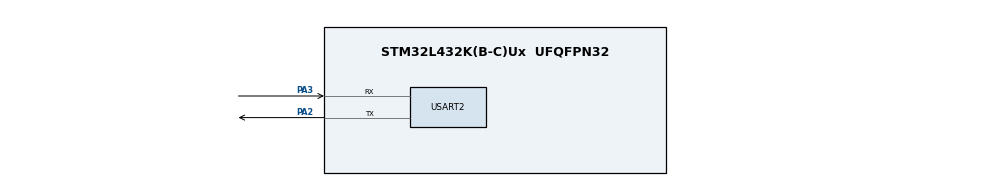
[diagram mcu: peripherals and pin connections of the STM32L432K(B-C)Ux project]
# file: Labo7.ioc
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Dma.Request0=USART2_RX
Dma.Request1=USART2_TX
Dma.USART2_RX.0.Direction=DMA_PERIPH_TO_MEMORY
Dma.USART2_RX.0.Instance=DMA1_Channel6
Dma.USART2_RX.0.MemDataAlignment=DMA_MDATAALIGN_BYTE
Dma.USART2_RX.0.MemInc=DMA_MINC_ENABLE
Dma.USART2_RX.0.Mode=DMA_NORMAL
Dma.USART2_RX.0.PeriphDataAlignment=DMA_PDATAALIGN_BYTE
Dma.USART2_RX.0.PeriphInc=DMA_PINC_DISABLE
Dma.USART2_RX.0.Priority=DMA_PRIORITY_LOW
Dma.USART2_TX.1.Direction=DMA_MEMORY_TO_PERIPH
Dma.USART2_TX.1.Instance=DMA1_Channel7
Dma.USART2_TX.1.MemDataAlignment=DMA_MDATAALIGN_BYTE
Dma.USART2_TX.1.MemInc=DMA_MINC_ENABLE
Dma.USART2_TX.1.Mode=DMA_NORMAL
Dma.USART2_TX.1.PeriphDataAlignment=DMA_PDATAALIGN_BYTE
Dma.USART2_TX.1.PeriphInc=DMA_PINC_DISABLE
Dma.USART2_TX.1.Priority=DMA_PRIORITY_LOW
Mcu.Family=STM32L4
Mcu.Name=STM32L432K(B-C)Ux
Mcu.Package=UFQFPN32
NVIC.DMA1_Channel6_IRQn=true\:0\:0\:false\:false\:true\:false\:true\:true
NVIC.DMA1_Channel7_IRQn=true\:0\:0\:false\:false\:true\:false\:true\:true
NVIC.PriorityGroup=NVIC_PRIORITYGROUP_4
PA2.Mode=Asynchronous
PA2.Signal=USART2_TX
PA3.Mode=Asynchronous
PA3.Signal=USART2_RX
ProjectManager.HeapSize=0x200
ProjectManager.StackSize=0x400
ProjectManager.TargetToolchain=STM32CubeIDE
RCC.HSE_VALUE=8000000
RCC.HSI48_VALUE=48000000
RCC.HSI_VALUE=16000000
RCC.LSE_VALUE=32768
RCC.MSI_VALUE=4000000
RCC.VCOOutputFreq_Value=32000000
USART2.VirtualMode-Asynchronous=VM_ASYNC
board=custom

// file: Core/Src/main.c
/* USER CODE BEGIN Header */
/**
  ******************************************************************************
  * @file           : main.c
  * @brief          : Main program body
  ******************************************************************************
  * @attention
  *
  * Copyright (c) 2022 STMicroelectronics.
  * All rights reserved.
  *
  * This software is licensed under terms that can be found in the LICENSE file
  * in the root directory of this software component.
  * If no LICENSE file comes with this software, it is provided AS-IS.
  *
  ******************************************************************************
  */
/* USER CODE END Header */
#include "main.h"

/* USER CODE BEGIN Includes */
#include "string.h"
/* USER CODE END Includes */

UART_HandleTypeDef huart2;
DMA_HandleTypeDef hdma_usart2_rx;
DMA_HandleTypeDef hdma_usart2_tx;

void SystemClock_Config(void);
static void MX_GPIO_Init(void);
static void MX_DMA_Init(void);
static void MX_USART2_UART_Init(void);

/* USER CODE BEGIN 0 */
//uint8_t dataArrived = 0;
uint8_t data[4] = "";
/* USER CODE END 0 */

int main(void)
{

  /* MCU Configuration--------------------------------------------------------*/

  /* Reset of all peripherals, Initializes the Flash interface and the Systick. */
  HAL_Init();

  /* Configure the system clock */
  SystemClock_Config();

  /* Initialize all configured peripherals */
  MX_GPIO_Init();
  MX_DMA_Init();
  MX_USART2_UART_Init();

  /* Infinite loop */
  /* USER CODE BEGIN WHILE */
  HAL_UART_Receive_DMA(&huart2, data, 4);
 // while(!dataArrived);
  while (1)
  {
    /* USER CODE END WHILE */
	  HAL_UART_Transmit_DMA(&huart2, (uint8_t*)"Hijo solo te veia y ve como amigo, ya basta por favor!!!\n\r", strlen("Gaby, Vid lleguen temprano por fa!!!\n\r"));
	  HAL_Delay(1000);
  }
}

void SystemClock_Config(void)
{
  RCC_OscInitTypeDef RCC_OscInitStruct = {0};
  RCC_ClkInitTypeDef RCC_ClkInitStruct = {0};

  /** Configure the main internal regulator output voltage
  */
  if (HAL_PWREx_ControlVoltageScaling(PWR_REGULATOR_VOLTAGE_SCALE1) != HAL_OK)
  {
    Error_Handler();
  }

  /** Initializes the RCC Oscillators according to the specified parameters
  * in the RCC_OscInitTypeDef structure.
  */
  RCC_OscInitStruct.OscillatorType = RCC_OSCILLATORTYPE_MSI;
  RCC_OscInitStruct.MSIState = RCC_MSI_ON;
  RCC_OscInitStruct.MSICalibrationValue = 0;
  RCC_OscInitStruct.MSIClockRange = RCC_MSIRANGE_6;
  RCC_OscInitStruct.PLL.PLLState = RCC_PLL_NONE;
  if (HAL_RCC_OscConfig(&RCC_OscInitStruct) != HAL_OK)
  {
    Error_Handler();
  }

  /** Initializes the CPU, AHB and APB buses clocks
  */
  RCC_ClkInitStruct.ClockType = RCC_CLOCKTYPE_HCLK|RCC_CLOCKTYPE_SYSCLK
                              |RCC_CLOCKTYPE_PCLK1|RCC_CLOCKTYPE_PCLK2;
  RCC_ClkInitStruct.SYSCLKSource = RCC_SYSCLKSOURCE_MSI;
  RCC_ClkInitStruct.AHBCLKDivider = RCC_SYSCLK_DIV1;
  RCC_ClkInitStruct.APB1CLKDivider = RCC_HCLK_DIV1;
  RCC_ClkInitStruct.APB2CLKDivider = RCC_HCLK_DIV1;

  if (HAL_RCC_ClockConfig(&RCC_ClkInitStruct, FLASH_LATENCY_0) != HAL_OK)
  {
    Error_Handler();
  }
}

static void MX_USART2_UART_Init(void)
{

  huart2.Instance = USART2;
  huart2.Init.BaudRate = 115200;
  huart2.Init.WordLength = UART_WORDLENGTH_8B;
  huart2.Init.StopBits = UART_STOPBITS_1;
  huart2.Init.Parity = UART_PARITY_NONE;
  huart2.Init.Mode = UART_MODE_TX_RX;
  huart2.Init.HwFlowCtl = UART_HWCONTROL_NONE;
  huart2.Init.OverSampling = UART_OVERSAMPLING_16;
  huart2.Init.OneBitSampling = UART_ONE_BIT_SAMPLE_DISABLE;
  huart2.AdvancedInit.AdvFeatureInit = UART_ADVFEATURE_NO_INIT;
  if (HAL_UART_Init(&huart2) != HAL_OK)
  {
    Error_Handler();
  }

}

static void MX_DMA_Init(void)
{

  /* DMA controller clock enable */
  __HAL_RCC_DMA1_CLK_ENABLE();

  /* DMA interrupt init */
  /* DMA1_Channel6_IRQn interrupt configuration */
  HAL_NVIC_SetPriority(DMA1_Channel6_IRQn, 0, 0);
  HAL_NVIC_EnableIRQ(DMA1_Channel6_IRQn);
  /* DMA1_Channel7_IRQn interrupt configuration */
  HAL_NVIC_SetPriority(DMA1_Channel7_IRQn, 0, 0);
  HAL_NVIC_EnableIRQ(DMA1_Channel7_IRQn);

}

static void MX_GPIO_Init(void)
{

  /* GPIO Ports Clock Enable */
  __HAL_RCC_GPIOA_CLK_ENABLE();

}

/* USER CODE BEGIN 4 */
void HAL_UART_RxHalfCpltCallback(UART_HandleTypeDef *huart) {
	HAL_UART_Transmit(&huart2, (uint8_t*)"hola", strlen("hola"), HAL_MAX_DELAY);
	//HAL_UART_Transmit_IT(&huart2, (uint8_t*)"mundo\n\r", strlen("mundo\n\r"));
}

//void HAL_UART_RxCpltCallback(UART_HandleTypeDef *huart) {
	//dataArrived = 1;
//}

/* USER CODE END 4 */

void Error_Handler(void)
{
  /* USER CODE BEGIN Error_Handler_Debug */
  /* User can add his own implementation to report the HAL error return state */
  //__disable_irq();
  //while (1)
  //{
  //}
  /* USER CODE END Error_Handler_Debug */
}
